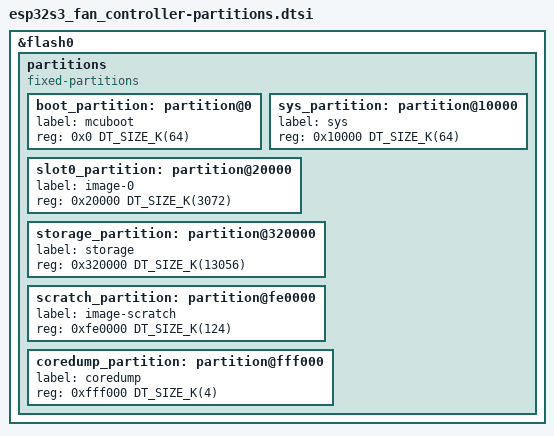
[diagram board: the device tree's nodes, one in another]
/*
 * Copyright (c) 2026
 *
 * SPDX-License-Identifier: Apache-2.0
 */

&flash0 {
	partitions {
		compatible = "fixed-partitions";
		#address-cells = <1>;
		#size-cells = <1>;

		boot_partition: partition@0 {
			label = "mcuboot";
			reg = <0x0 DT_SIZE_K(64)>;
		};

		sys_partition: partition@10000 {
			label = "sys";
			reg = <0x10000 DT_SIZE_K(64)>;
		};

		slot0_partition: partition@20000 {
			label = "image-0";
			reg = <0x20000 DT_SIZE_K(3072)>;
		};

		storage_partition: partition@320000 {
			label = "storage";
			reg = <0x320000 DT_SIZE_K(13056)>;
		};

		scratch_partition: partition@fe0000 {
			label = "image-scratch";
			reg = <0xfe0000 DT_SIZE_K(124)>;
		};

		coredump_partition: partition@fff000 {
			label = "coredump";
			reg = <0xfff000 DT_SIZE_K(4)>;
		};
	};
};

/* Remaining flash size is 0kB
 * Last used address is 0xFFFFFF
 */
